AUTOSAR XML (schema 00048)
package /ComponentTypes
  swc implementation Common_Safety_Implementation: behavior=Common_Safety_InternalBehavior
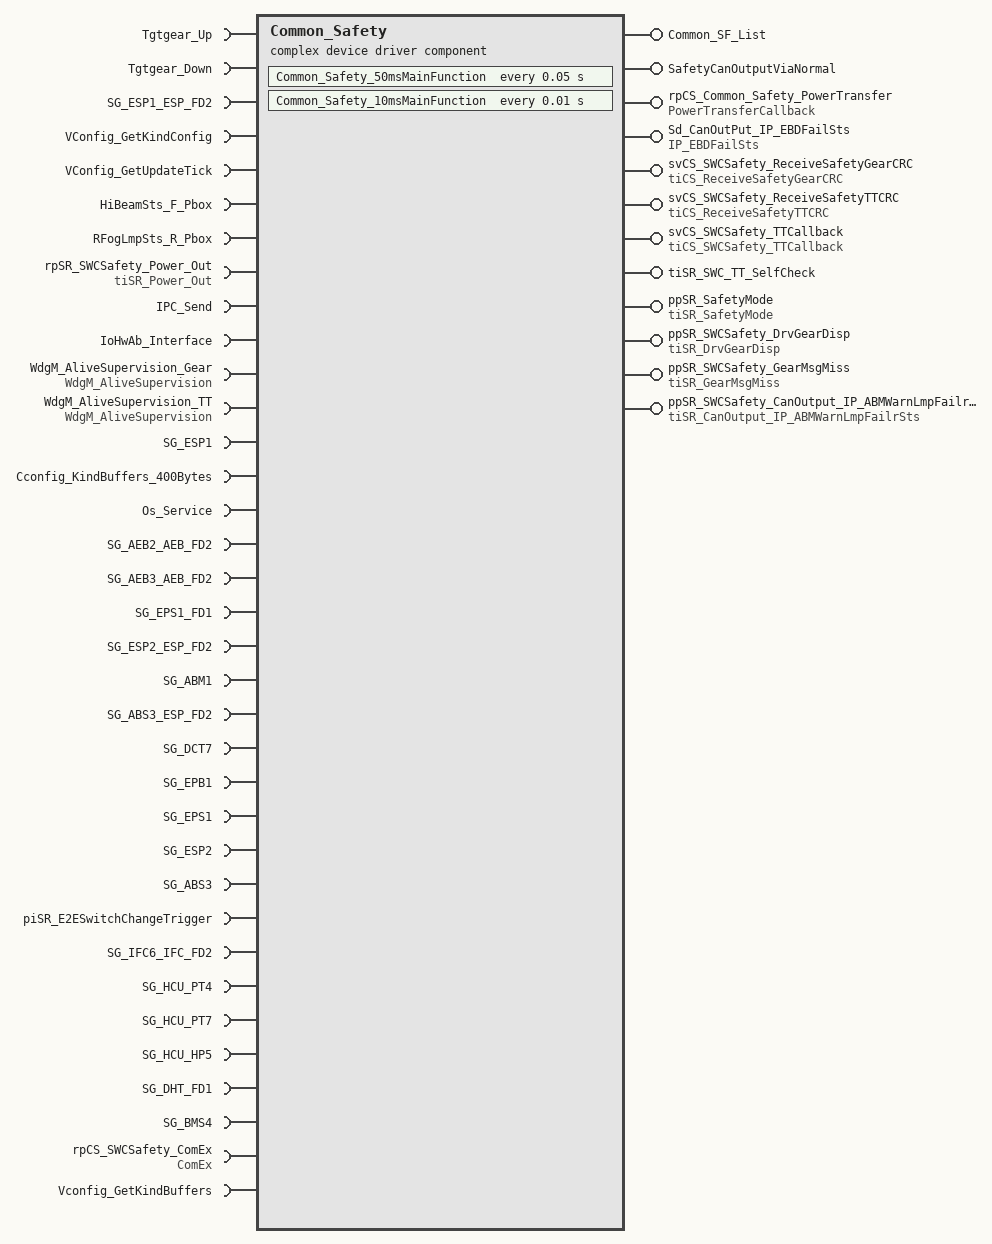
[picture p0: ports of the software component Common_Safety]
  complex device driver sw component type Common_Safety
    5 x require port:
      Tgtgear_Up: nonqueued-receiver-com-spec{data-element=Tgtgear_Up, alive-timeout=0.2, enable-update=true, filter=data-filter-type=ALWAYS, handle-never-received=true, init-value=0}, required-interface=Tgtgear_Up
      Tgtgear_Down: nonqueued-receiver-com-spec{data-element=Tgtgear_Down, alive-timeout=0.2, enable-update=true, filter=data-filter-type=ALWAYS, handle-never-received=true, init-value=0}, required-interface=Tgtgear_Down
      SG_ESP1_ESP_FD2: nonqueued-receiver-com-spec{data-element=SG_ESP1_ESP_FD2, uses-end-to-end-protection=true, alive-timeout=0.2, enable-update=true, handle-never-received=true, init-value=fields=[BTCActv_0x137:0, CheckSum_ESP1_0x137:0, dummy_ESP_FD2_16:0, dummy_ESP_FD2_17:0, dummy_ESP_FD2_18:0, dummy_ESP_FD2_19:0, dummy_ESP_FD2_20:0, ESP_MasterCylBrkPress_0x137:0, ESP_MasterCylBrkPressVld_0x137:0, ESPActvInfoLmp_0x137:0, ESPBrkLmpCtrl_0x137:0, ESPFailSts_0x137:0, ESPFuncOffSts_0x137:0, MSRActv_0x137:0, PTCActv_0x137:0, RollingCounter_ESP1_0x137:0, VDCActv_0x137:0]}, required-interface=SG_ESP1_ESP_FD2
      VConfig_GetKindConfig: client-com-spec=Operation_VConfig_GetKindConfig, required-interface=VConfig_GetKindConfig
      VConfig_GetUpdateTick: client-com-spec=OperationVConfig_GetUpdateTick, required-interface=VConfig_GetUpdateTick
    provide port Common_SF_List: provided-com-specs=[{operation=Deinit, queue-length=1}, {operation=Int, queue-length=1}], provided-interface=Common_SF_List
    5 x require port:
      HiBeamSts_F_Pbox: nonqueued-receiver-com-spec{data-element=HiBeamSts_F_Pbox, alive-timeout=0.5, filter=data-filter-type=ALWAYS, handle-never-received=true, init-value=0}, required-interface=HiBeamSts_F_Pbox
      RFogLmpSts_R_Pbox: nonqueued-receiver-com-spec{data-element=RFogLmpSts_R_Pbox, alive-timeout=0.5, filter=data-filter-type=ALWAYS, handle-never-received=true, init-value=0}, required-interface=RFogLmpSts_R_Pbox
      rpSR_SWCSafety_Power_Out: nonqueued-receiver-com-spec{data-element=SystemStateOut, filter=data-filter-type=ALWAYS}, required-interface=tiSR_Power_Out
      IPC_Send: client-com-spec=IPC_Send, required-interface=IPC_Send
      IoHwAb_Interface: required-com-specs=[SetHsLsOutput, SetPeriodAndDuty, SetDuty, SetPin, GetPin, GetVoltage], required-interface=IoHwAb_Interface
    provide port SafetyCanOutputViaNormal: provided-interface=SafetyCanOutputViaNormal
      provided-com-specs:
        data-element=CheckSum_IP2, init-value=0
        data-element=RollingCounter_IP2, init-value=0
        data-element=IP_VINcompr, init-value=0
        data-element=IP_VehTotDistanceValid, init-value=0
        data-element=IP_VehTotDistance, init-value=0
        data-element=IP_PassSeatBeltWarnLmpFailSts, init-value=0
        data-element=IP_VehSpdUnit, init-value=0
        data-element=IP_FuelLvlInfo, init-value=0
        data-element=IP_FuelLvlLowLmpSts, init-value=0
        data-element=IP_Err, init-value=0
        data-element=IP_EngOilPressLowLmpSts, init-value=0
        data-element=IP_DrvSeatBeltWarnLmpFailSts, init-value=0
        data-element=IP_BattChrgLmpSts, init-value=0
        data-element=IP_ACCErr, init-value=0
        data-element=IP_ABMWarnLmpFailrSts, init-value=0
        data-element=dummy_HUT_IP2_0, init-value=0
        data-element=IP_RemainDistance, init-value=0
        data-element=IP_InstFuelConsUnit, init-value=0
        data-element=IP_AvgFuelCons, init-value=0
        data-element=IP_InstFuelCons, init-value=0
        data-element=IP_CurrTheme, init-value=0
        data-element=IP_VehSpdDisp, init-value=0
        data-element=IP_FuelMainTankR, init-value=0
        data-element=IP_FuelAuxTankR, init-value=0
        data-element=IP_VelSpdDisp_Mile, init-value=0
        data-element=IP_LagueSet, init-value=0
        data-element=IP_EBDFailSts, init-value=0
    require port WdgM_AliveSupervision_Gear: client-com-spec=CheckpointReached, required-interface=WdgM_AliveSupervision
    require port WdgM_AliveSupervision_TT: client-com-spec=CheckpointReached, required-interface=WdgM_AliveSupervision
    provide port rpCS_Common_Safety_PowerTransfer: provided-com-specs=[{operation=Nomal2StandbyCallback, queue-length=1}, {operation=Standby2NomalCallback, queue-length=1}], provided-interface=PowerTransferCallback
    require port SG_ESP1: nonqueued-receiver-com-spec{data-element=SG_ESP1, uses-end-to-end-protection=true, alive-timeout=0.2, enable-update=true, handle-never-received=true, init-value=fields=[BTCActv_0x149:0, CheckSum_ESP1_0x149:0, dummy_ESP1_0:0, dummy_ESP1_1:0, dummy_ESP1_2:0, dummy_ESP1_3:0, dummy_ESP1_4:0, ESP_MasterCylBrkPress_0x149:0, ESP_MasterCylBrkPressVld_0x149:1, ESPActvInfoLmp_0x149:0, ESPBrkLmpCtrl_0x149:0, ESPFailSts_0x149:0, ESPFuncOffSts_0x149:0, MSRActv_0x149:0, PTCActv_0x149:0, RollingCounter_ESP1_0x149:0, VDCActv_0x149:0]}, required-interface=SG_ESP1
    provide port Sd_CanOutPut_IP_EBDFailSts: nonqueued-sender-com-spec{data-element=IP_EBDFailSts, init-value=0}, provided-interface=IP_EBDFailSts
    require port Cconfig_KindBuffers_400Bytes: nonqueued-receiver-com-spec{data-element=CconfigKind_400Bytes, filter=data-filter-type=ALWAYS, init-value=400 x 0}, required-interface=Cconfig_KindBuffers_400Bytes
    require port Os_Service: required-com-specs=[GetElapsedValue, GetCounterValue], required-interface=Os_Service
    provide port svCS_SWCSafety_ReceiveSafetyGearCRC: server-com-spec{operation=Callback, queue-length=1}, provided-interface=tiCS_ReceiveSafetyGearCRC
    provide port svCS_SWCSafety_ReceiveSafetyTTCRC: server-com-spec{operation=Callback, queue-length=1}, provided-interface=tiCS_ReceiveSafetyTTCRC
    12 x require port:
      SG_AEB2_AEB_FD2: nonqueued-receiver-com-spec{data-element=SG_AEB2_AEB_FD2, uses-end-to-end-protection=true, alive-timeout=0.5, enable-update=true, handle-never-received=true, init-value=fields=[AEB_JA_Resp:1, AEB_PedResp:1, AEB_VehResp:1, Checksum_AEB2:0, FCW_Snvty:0, RollingCounter_AEB2:0, dummy_AEB_FD2_8:0, dummy_AEB_FD2_9:0, dummy_AEB_FD2_10:0, dummy_AEB_FD2_11:0, dummy_AEB_FD2_12:0, dummy_AEB_FD2_13:0, dummy_AEB_FD2_14:0]}, required-interface=SG_AEB2_AEB_FD2
      SG_AEB3_AEB_FD2: nonqueued-receiver-com-spec{data-element=SG_AEB3_AEB_FD2, uses-end-to-end-protection=true, alive-timeout=0.5, enable-update=true, handle-never-received=true, init-value=fields=[AEB_JA_Warn:0, AEB_JABrkTrig:0, AEB_JAFuncSts:0, AEB_PedTrig:0, AEB_VehTrig:0, Checksum_AEB3:0, FCW_AEB_PedFctSts:0, FCW_AEB_VehFctSts:0, FCW_Warn:0, RollingCounter_AEB3:0, dummy_AEB_FD2_15:0, dummy_AEB_FD2_16:0, dummy_AEB_FD2_17:0, dummy_AEB_FD2_18:0, dummy_AEB_FD2_19:0, dummy_AEB_FD2_20:0, dummy_AEB_FD2_21:0]}, required-interface=SG_AEB3_AEB_FD2
      SG_EPS1_FD1: nonqueued-receiver-com-spec{data-element=SG_EPS1_FD1, uses-end-to-end-protection=true, alive-timeout=0.2, enable-update=true, handle-never-received=true, init-value=fields=[CheckSum_EPS1_0x147:0, dummy_EPS_FD1_0:0, dummy_EPS_FD1_1:0, dummy_EPS_FD1_2:0, dummy_EPS_FD1_3:0, dummy_EPS_FD1_4:0, dummy_EPS_FD1_5:0, dummy_EPS_FD1_6:0, dummy_EPS_FD1_7:0, EPS_FailSts_0x147:0, EPS_SteerMod_0x147:0, EPS_TrqSnsrSts_0x147:0, RollingCounter_EPS1_0x147:0]}, required-interface=SG_EPS1_FD1
      SG_ESP2_ESP_FD2: nonqueued-receiver-com-spec{data-element=SG_ESP2_ESP_FD2, uses-end-to-end-protection=true, alive-timeout=0.2, enable-update=true, handle-never-received=true, init-value=fields=[ABAActv_0x137:0, ABAavailable_0x137:0, ABPActv_0x137:0, ABPAvailable_0x137:0, AEBAvailable_0x137:0, AEBBAActv_0x137:0, AEBIBActv_0x137:0, AVHErrSts_0x137:0, AVHSts_0x137:0, AWBActv_0x137:0, AWBAvailable_0x137:0, BrkDskOvrheatd_0x137:0, CDDActv_0x137:0, CDDAvailable_0x137:0, CDPActv_0x137:0, CheckSum_ESP2_0x137:0, dummy_ESP_FD2_8:0, dummy_ESP_FD2_9:0, dummy_ESP_FD2_10:0, dummy_ESP_FD2_11:0, dummy_ESP_FD2_12:0, dummy_ESP_FD2_13:0, dummy_ESP_FD2_14:0, dummy_ESP_FD2_15:0, HDCCtrl_0x137:0, HDCFault_0x137:0, NoBrkForce_0x137:0, RollingCounter_ESP2_0x137:0, VehStandstill_0x137:0]}, required-interface=SG_ESP2_ESP_FD2
      SG_ABM1: nonqueued-receiver-com-spec{data-element=SG_ABM1, uses-end-to-end-protection=true, alive-timeout=5, enable-update=true, handle-never-received=true, init-value=fields=[AirbFailLmpCmd:0, CheckSum_ABM1:0, DrvSBR:0, DrvSBR_Visual:0, PassSBR:0, PassSBR_Visual:0, RollingCounter_ABM1:0, SecRowLSBR:0, SecRowLSBR_Visual:0, SecRowMidSBR:0, SecRowMidSBR_Visual:0, SecRowRSBR:0, SecRowRSBR_Visual:0, CrashOutputSts:0, dummy_ABM1_0:0, dummy_ABM1_1:0, dummy_ABM1_2:0, dummy_ABM1_3:0, dummy_ABM1_4:0, dummy_ABM1_5:0]}, required-interface=SG_ABM1
      SG_ABS3_ESP_FD2: nonqueued-receiver-com-spec{data-element=SG_ABS3_ESP_FD2, uses-end-to-end-protection=true, alive-timeout=0.2, enable-update=true, handle-never-received=true, init-value=fields=[ABSActv_0x137:0, ABSFailSts_0x137:1, CheckSum_ABS3_0x137:0, dummy_ESP_FD2_37:0, dummy_ESP_FD2_38:0, dummy_ESP_FD2_39:0, dummy_ESP_FD2_40:0, EBDActv_0x137:0, EBDFailSts_0x137:0, RollingCounter_ABS3_0x137:0, VehOdoInfo_0x137:0, VehOdoInfoSts_0x137:1, VehSpd_0x137:0, VehSpdVld_0x137:0]}, required-interface=SG_ABS3_ESP_FD2
      SG_DCT7: nonqueued-receiver-com-spec{data-element=SG_DCT7, uses-end-to-end-protection=true, alive-timeout=0.5, enable-update=true, handle-never-received=true, init-value=fields=[CheckSum_DCT7:0, DCT_PrsBrk_Warn:0, DCT_RaceModeSts:0, DCT_ShftNotAlwd_Warn:0, DCT_ShftRecom_M:0, DrvAutoGearDisp:0, DrvWarnMsg:0, RollingCounter_DCT7:0, DrvFaiMsg_0x235:0, DrvGearDispSts_0x235:0, DrvModDisp_0x235:0, DrvModDispSts_0x235:0, dummy_DCT7_0:0, dummy_DCT7_1:0, dummy_DCT7_2:0, dummy_DCT7_3:0, dummy_DCT7_4:0, dummy_DCT7_5:0]}, required-interface=SG_DCT7
      SG_EPB1: nonqueued-receiver-com-spec{data-element=SG_EPB1, uses-end-to-end-protection=true, alive-timeout=0.2, enable-update=true, handle-never-received=true, init-value=fields=[CheckSum_EPB1:0, EPBErrSts:0, EPBRedLmpSts:0, EPBSts:0, EPBTextDisp:0, PressBrakePedalPointOut:0, RollingCounter_EPB1:0, dummy_EPB1_0:0, dummy_EPB1_1:0, dummy_EPB1_2:0, dummy_EPB1_3:0, dummy_EPB1_4:0, dummy_EPB1_5:0, dummy_EPB1_6:0, dummy_EPB1_7:0]}, required-interface=SG_EPB1
      SG_EPS1: nonqueued-receiver-com-spec{data-element=SG_EPS1, uses-end-to-end-protection=true, alive-timeout=0.2, enable-update=true, handle-never-received=true, init-value=fields=[CheckSum_EPS1_0x168:0, dummy_EPS1_0:0, dummy_EPS1_1:0, dummy_EPS1_2:0, dummy_EPS1_3:0, dummy_EPS1_4:0, dummy_EPS1_5:0, dummy_EPS1_6:0, dummy_EPS1_7:0, EPS_FailSts_0x168:0, EPS_SteerMod_0x168:0, EPS_TrqSnsrSts_0x168:1, RollingCounter_EPS1_0x168:0]}, required-interface=SG_EPS1
      SG_ESP2: nonqueued-receiver-com-spec{data-element=SG_ESP2, uses-end-to-end-protection=true, alive-timeout=0.2, enable-update=true, handle-never-received=true, init-value=fields=[DrivingModDis:0, DrivingModReq_ESP:0, TAB_Available:0, TAB_Sts:0, ABAActv_0x145:0, ABAavailable_0x145:0, ABPActv_0x145:0, ABPAvailable_0x145:0, AEBAvailable_0x145:0, AEBBAActv_0x145:0, AEBIBActv_0x145:0, AVHErrSts_0x145:0, AVHSts_0x145:0, AWBActv_0x145:0, AWBAvailable_0x145:0, BrkDskOvrheatd_0x145:0, CDDActv_0x145:0, CDDAvailable_0x145:0, CDPActv_0x145:0, CheckSum_ESP2_0x145:0, dummy_ESP2_0:0, dummy_ESP2_1:0, dummy_ESP2_2:0, dummy_ESP2_3:0, dummy_ESP2_4:0, dummy_ESP2_5:0, dummy_ESP2_6:0, dummy_ESP2_7:0, HDCCtrl_0x145:0, HDCFault_0x145:0, NoBrkForce_0x145:0, RollingCounter_ESP2_0x145:0, VehStandstill_0x145:0]}, required-interface=SG_ESP2
      SG_ABS3: nonqueued-receiver-com-spec{data-element=SG_ABS3, uses-end-to-end-protection=true, alive-timeout=0.2, enable-update=true, handle-never-received=true, init-value=fields=[ABSActv_0x265:0, ABSFailSts_0x265:1, CheckSum_ABS3_0x265:0, dummy_ABS3_0:0, dummy_ABS3_1:0, dummy_ABS3_2:0, dummy_ABS3_3:0, EBDActv_0x265:0, EBDFailSts_0x265:0, RollingCounter_ABS3_0x265:0, VehOdoInfo_0x265:0, VehOdoInfoSts_0x265:1, VehSpd_0x265:0, VehSpdVld_0x265:0]}, required-interface=SG_ABS3
      piSR_E2ESwitchChangeTrigger: nonqueued-receiver-com-spec{data-element=Element, filter=data-filter-type=ALWAYS, init-value=0}, required-interface=piSR_E2ESwitchChangeTrigger
    provide port svCS_SWCSafety_TTCallback: server-com-spec{operation=Operation, queue-length=1}, provided-interface=tiCS_SWCSafety_TTCallback
    provide port tiSR_SWC_TT_SelfCheck: nonqueued-sender-com-spec{data-element=Element, init-value=0}, provided-interface=tiSR_SWC_TT_SelfCheck
    provide port ppSR_SafetyMode: server-com-spec{operation=Operation, queue-length=1}, provided-interface=tiSR_SafetyMode
    7 x require port:
      SG_IFC6_IFC_FD2: nonqueued-receiver-com-spec{data-element=SG_IFC6_IFC_FD2, uses-end-to-end-protection=true, alive-timeout=0.5, enable-update=true, filter=data-filter-type=ALWAYS, handle-never-received=true, init-value=fields=[Checksum_IFC6:0, dummy_IFC_FD2_17:0, dummy_IFC_FD2_18:0, dummy_IFC_FD2_19:0, dummy_IFC_FD2_20:0, IFC_NextLeLane_dy:2496, IFC_NextRiLane_dy:2496, RollingCounter_IFC6:0]}, required-interface=SG_IFC6_IFC_FD2
      SG_HCU_PT4: nonqueued-receiver-com-spec{data-element=SG_HCU_PT4, uses-end-to-end-protection=true, alive-timeout=1, enable-update=true, filter=data-filter-type=ALWAYS, handle-never-received=true, init-value=fields=[CarWashMode_Sts:0, CarWashMode_StsDisp:0, Checksum_HCU_PT4:0, dummy_HCU_PT4_0:0, dummy_HCU_PT4_1:0, dummy_HCU_PT4_2:0, dummy_HCU_PT4_3:0, dummy_HCU_PT4_4:0, dummy_HCU_PT4_5:0, dummy_HCU_PT4_6:0, dummy_HCU_PT4_7:0, HCU_ACStsReq:2, HCU_BattPowerRedWarn:0, HCU_ConnectChrgLine_Indcn:0, HCU_EgyRecFB:0, HCU_EnerSavePowerMod:0, HCU_InhbChrgInfo:0, HCU_OilTankCoverSts:0, HCU_OPDFail:0, HCU_RefuReq:0, HCU_RemoveChrgLine_Indcn:0, HCU_Shift_P_Indcn:0, HCU_SOCLow_Indcn:0, HCU_WadeModeSetSts:0, OPDParkWarnReq:0, RollingCounter_HCU_PT4:0]}, required-interface=SG_HCU_PT4
      SG_HCU_PT7: nonqueued-receiver-com-spec{data-element=SG_HCU_PT7, uses-end-to-end-protection=true, alive-timeout=0.5, enable-update=true, filter=data-filter-type=ALWAYS, handle-never-received=true, init-value=fields=[CheckSum_HCU_PT7:0, dummy_HCU_PT7_0:0, dummy_HCU_PT7_1:0, dummy_HCU_PT7_2:0, dummy_HCU_PT7_3:0, dummy_HCU_PT7_4:0, dummy_HCU_PT7_5:0, dummy_HCU_PT7_6:0, HCU_12VSysErr_1:0, HCU_12VSysErr_2:0, HCU_12VSysErrLmpSts:0, HCU_EnrgFlowInd:0, HCU_HybSysErr_1:0, HCU_HybSysErr_2:0, HCU_HybSysErr_3:0, HCU_HybSysErr_4:0, HCU_HybSysErr_5:0, HCU_HybSysErr_6:0, HCU_HybSysErr_7:0, HCU_HybSysErrLmpSts:0, HCU_ModSwtFail:0, HCU_OPDLmpSts:0, HCU_OPDSts:0, HCU_PowerRedWarnLmpCmd:0, HCU_RdyLmpSts:0, RollingCounter_HCU_PT7:0]}, required-interface=SG_HCU_PT7
      SG_HCU_HP5: nonqueued-receiver-com-spec{data-element=SG_HCU_HP5, uses-end-to-end-protection=true, alive-timeout=0.5, enable-update=true, filter=data-filter-type=ALWAYS, handle-never-received=true, init-value=fields=[Checksum_HCU_HP5:0, DrvFaiMsg_0x201:0, DrvGearDisp:0, DrvGearDispSts_0x201:0, DrvModDisp_0x201:0, DrvModDispSts_0x201:0, dummy_HCU_HP5_0:0, dummy_HCU_HP5_1:0, dummy_HCU_HP5_2:0, dummy_HCU_HP5_3:0, dummy_HCU_HP5_4:0, HCU_EnrgFlowInd_DHT:0, HCU_PrsBrkWarn:0, HCU_ShftNotAlwd_Warn:0, RollingCounter_HCU_HP5:0]}, required-interface=SG_HCU_HP5
      SG_DHT_FD1: nonqueued-receiver-com-spec{data-element=SG_DHT_FD1, uses-end-to-end-protection=true, alive-timeout=0.1, enable-update=true, filter=data-filter-type=ALWAYS, handle-never-received=true, init-value=fields=[CheckSum_DHT1:0, dummy_DHT_FD1_8:0, dummy_DHT_FD1_9:0, dummy_DHT_FD1_10:0, dummy_DHT_FD1_11:0, dummy_DHT_FD1_12:0, dummy_DHT_FD1_13:0, RollingCounter_DHT1:0, TCU_ClutchHotWarning:0, TCU_ErrCategory:0]}, required-interface=SG_DHT_FD1
      SG_BMS4: nonqueued-receiver-com-spec{data-element=SG_BMS4, uses-end-to-end-protection=true, alive-timeout=0.1, enable-update=true, filter=data-filter-type=ALWAYS, handle-never-received=true, init-value=fields=[BMS_BattPoweErr:0, BMS_ErrCategory:0, BMS_PackCurr:0, BMS_PackVolt:178, BMS_PowerDownCmplt:0, CheckSum_BMS4:0, dummy_BMS4_0:0, dummy_BMS4_1:0, dummy_BMS4_2:0, dummy_BMS4_3:0, dummy_BMS4_4:0, RollingCounter_BMS4:0]}, required-interface=SG_BMS4
      rpCS_SWCSafety_ComEx: required-com-specs=[SendSignal, ReceiveSignal, GetRxE2EStatus], required-interface=ComEx
    provide port ppSR_SWCSafety_DrvGearDisp: nonqueued-sender-com-spec{data-element=Element, init-value=0}, provided-interface=tiSR_DrvGearDisp
    provide port ppSR_SWCSafety_GearMsgMiss: nonqueued-sender-com-spec{data-element=Element, init-value=0}, provided-interface=tiSR_GearMsgMiss
    require port Vconfig_GetKindBuffers: nonqueued-receiver-com-spec{data-element=AllKinds, filter=data-filter-type=ALWAYS, init-value=600 x 0}, required-interface=Vconfig_GetKindBuffers
    provide port ppSR_SWCSafety_CanOutput_IP_ABMWarnLmpFailrSts: nonqueued-sender-com-spec{data-element=Element, init-value=0}, provided-interface=tiSR_CanOutput_IP_ABMWarnLmpFailrSts
    behavior Common_Safety_InternalBehavior: data-type-mapping=[DataTypeMappings_DEV, DataTypeMappings_DEV], port-api-option{enable-take-address=true, error-handling=NO-TRANSFORMER-ERROR-HANDLING, indirect-api=false, port=Common_SF_List}
      exclusive area ExclusiveArea_Safety
      init event Gear_InitEvent: start-on-event=Common_Safety_Init
      timing event TMT_Gear_MainFunction: start-on-event=Common_Safety_50msMainFunction, period=0.05
      timing event TMT_TT_MainFunction: start-on-event=Common_Safety_10msMainFunction, period=0.01
      8 x operation invoked event:
        OIT_Common_SF_List_Deinit_Common_SF_List_Deinit: start-on-event=Common_SF_List_Deinit, operation=Common_SF_List.Deinit
        OIT_Common_SF_List_Int_Common_SF_List_Int: start-on-event=Common_SF_List_Int, operation=Common_SF_List.Int
        OIT_Common_Safety_Nomal2Standby_Callbcak_rpCS_Common_Safety_PowerTransfer_Nomal2StandbyCallback: start-on-event=Common_Safety_Nomal2Standby_Callbcak, operation=rpCS_Common_Safety_PowerTransfer.Nomal2StandbyCallback
        OIT_Common_GateWay_Standby2Nomal_Callbcak_rpCS_Common_Safety_PowerTransfer_Standby2NomalCallback: start-on-event=Common_Safety_Standby2Nomal_Callbcak, operation=rpCS_Common_Safety_PowerTransfer.Standby2NomalCallback
        OIT_Runnable_svCS_SWCSafety_ReceiveSafetyGearCRC_Callback: start-on-event=svCS_SWCSafety_ReceiveSafetyGearCRC_Callback, operation=svCS_SWCSafety_ReceiveSafetyGearCRC.Callback
        OIT_Runnable_svCS_SWCSafety_ReceiveSafetyTTCRC_Callback: start-on-event=svCS_SWCSafety_ReceiveSafetyTTCRC_Callback, operation=svCS_SWCSafety_ReceiveSafetyTTCRC.Callback
        OIT_svCS_SWCSafety_TTCallback_Operation_svCS_SWCSafety_TTCallback_Operation: start-on-event=svCS_SWCSafety_TTCallback_Operation, operation=svCS_SWCSafety_TTCallback.Operation
        OIT_ppSR_SafetyMode_Operation_ppSR_SafetyMode_Operation: start-on-event=SafetyMode_Operation, operation=ppSR_SafetyMode.Operation
      11 x runnable:
        Common_Safety_Init
        Common_Safety_50msMainFunction: can-enter-exclusive-area=ExclusiveArea_Safety
          data-read-access:
            access REC_rpSR_SWCSafety_Power_Out_SystemStateOut: accessed-variable=rpSR_SWCSafety_Power_Out.SystemStateOut
          data-receive-point-by-arguments:
            5 x access:
              REC_Tgtgear_Down_Tgtgear_Down: accessed-variable=Tgtgear_Down.Tgtgear_Down
              REC_Tgtgear_Up_Tgtgear_Up: accessed-variable=Tgtgear_Up.Tgtgear_Up
              REC_SG_ESP1_ESP_FD2_SG_ESP1_ESP_FD2: accessed-variable=SG_ESP1_ESP_FD2.SG_ESP1_ESP_FD2
              REC_HiBeamSts_F_Pbox_HiBeamSts_F_Pbox: accessed-variable=HiBeamSts_F_Pbox.HiBeamSts_F_Pbox
              REC_RFogLmpSts_R_Pbox_RFogLmpSts_R_Pbox: accessed-variable=RFogLmpSts_R_Pbox.RFogLmpSts_R_Pbox
          data-send-points:
            access SEND_ppSR_SWCSafety_DrvGearDisp_Element: accessed-variable=ppSR_SWCSafety_DrvGearDisp.Element
            access SEND_ppSR_SWCSafety_GearMsgMiss_Element: accessed-variable=ppSR_SWCSafety_GearMsgMiss.Element
          sync call SC_IPC_Send_IPC_Send: operation=IPC_Send.IPC_Send
          sync call SC_WdgM_AliveSupervision_Gear_CheckpointReached: operation=WdgM_AliveSupervision_Gear.CheckpointReached
        Common_Safety_10msMainFunction: can-enter-exclusive-area=ExclusiveArea_Safety
          data-read-access:
            access REC_rpSR_SWCSafety_Power_Out_SystemStateOut: accessed-variable=rpSR_SWCSafety_Power_Out.SystemStateOut
          data-receive-point-by-arguments:
            26 x access:
              REC_HiBeamSts_F_Pbox_HiBeamSts_F_Pbox: accessed-variable=HiBeamSts_F_Pbox.HiBeamSts_F_Pbox
              REC_RFogLmpSts_R_Pbox_RFogLmpSts_R_Pbox: accessed-variable=RFogLmpSts_R_Pbox.RFogLmpSts_R_Pbox
              REC_SG_ESP1_ESP_FD2_SG_ESP1_ESP_FD2: accessed-variable=SG_ESP1_ESP_FD2.SG_ESP1_ESP_FD2
              REC_Tgtgear_Down_Tgtgear_Down: accessed-variable=Tgtgear_Down.Tgtgear_Down
              REC_Tgtgear_Up_Tgtgear_Up: accessed-variable=Tgtgear_Up.Tgtgear_Up
              REC_SG_ESP1_SG_ESP1: accessed-variable=SG_ESP1.SG_ESP1
              REC_Cconfig_KindBuffers_400Bytes_CconfigKind_400Bytes: accessed-variable=Cconfig_KindBuffers_400Bytes.CconfigKind_400Bytes
              REC_SG_AEB2_AEB_FD2_SG_AEB2_AEB_FD2: accessed-variable=SG_AEB2_AEB_FD2.SG_AEB2_AEB_FD2
              REC_SG_AEB3_AEB_FD2_SG_AEB3_AEB_FD2: accessed-variable=SG_AEB3_AEB_FD2.SG_AEB3_AEB_FD2
              REC_SG_EPS1_FD1_SG_EPS1_FD1: accessed-variable=SG_EPS1_FD1.SG_EPS1_FD1
              REC_SG_ESP2_ESP_FD2_SG_ESP2_ESP_FD2: accessed-variable=SG_ESP2_ESP_FD2.SG_ESP2_ESP_FD2
              REC_SG_ABM1_SG_ABM1: accessed-variable=SG_ABM1.SG_ABM1
              REC_SG_ABS3_ESP_FD2_SG_ABS3_ESP_FD2: accessed-variable=SG_ABS3_ESP_FD2.SG_ABS3_ESP_FD2
              REC_SG_DCT7_SG_DCT7: accessed-variable=SG_DCT7.SG_DCT7
              REC_SG_EPB1_SG_EPB1: accessed-variable=SG_EPB1.SG_EPB1
              REC_SG_EPS1_SG_EPS1: accessed-variable=SG_EPS1.SG_EPS1
              REC_SG_ESP2_SG_ESP2: accessed-variable=SG_ESP2.SG_ESP2
              REC_SG_ABS3_SG_ABS3: accessed-variable=SG_ABS3.SG_ABS3
              REC_piSR_E2ESwitchChangeTrigger_Element: accessed-variable=piSR_E2ESwitchChangeTrigger.Element
              REC_SG_IFC6_IFC_FD2_SG_IFC6_IFC_FD2: accessed-variable=SG_IFC6_IFC_FD2.SG_IFC6_IFC_FD2
              REC_SG_HCU_PT4_SG_HCU_PT4: accessed-variable=SG_HCU_PT4.SG_HCU_PT4
              REC_SG_HCU_PT7_SG_HCU_PT7: accessed-variable=SG_HCU_PT7.SG_HCU_PT7
              REC_SG_BMS4_SG_BMS4: accessed-variable=SG_BMS4.SG_BMS4
              REC_SG_DHT_FD1_SG_DHT_FD1: accessed-variable=SG_DHT_FD1.SG_DHT_FD1
              REC_SG_HCU_HP5_SG_HCU_HP5: accessed-variable=SG_HCU_HP5.SG_HCU_HP5
              REC_Vconfig_GetKindBuffers_Kind600Bytes: accessed-variable=Vconfig_GetKindBuffers.AllKinds
          data-send-points:
            19 x access:
              SEND_SafetyCanOutputViaNormal_Element: accessed-variable=SafetyCanOutputViaNormal.CheckSum_IP2
              SEND_SafetyCanOutputViaNormal_IP_ABMWarnLmpFailrSts: accessed-variable=SafetyCanOutputViaNormal.IP_ABMWarnLmpFailrSts
              SEND_SafetyCanOutputViaNormal_IP_ACCErr: accessed-variable=SafetyCanOutputViaNormal.IP_ACCErr
              SEND_SafetyCanOutputViaNormal_IP_BattChrgLmpSts: accessed-variable=SafetyCanOutputViaNormal.IP_BattChrgLmpSts
              SEND_SafetyCanOutputViaNormal_IP_DrvSeatBeltWarnLmpFailSts: accessed-variable=SafetyCanOutputViaNormal.IP_DrvSeatBeltWarnLmpFailSts
              SEND_SafetyCanOutputViaNormal_IP_EngOilPressLowLmpSts: accessed-variable=SafetyCanOutputViaNormal.IP_EngOilPressLowLmpSts
              SEND_SafetyCanOutputViaNormal_IP_Err: accessed-variable=SafetyCanOutputViaNormal.IP_Err
              SEND_SafetyCanOutputViaNormal_IP_FuelLvlInfo: accessed-variable=SafetyCanOutputViaNormal.IP_FuelLvlInfo
              SEND_SafetyCanOutputViaNormal_IP_FuelLvlLowLmpSts: accessed-variable=SafetyCanOutputViaNormal.IP_FuelLvlLowLmpSts
              SEND_SafetyCanOutputViaNormal_IP_PassSeatBeltWarnLmpFailSts: accessed-variable=SafetyCanOutputViaNormal.IP_PassSeatBeltWarnLmpFailSts
              SEND_SafetyCanOutputViaNormal_IP_VINcompr: accessed-variable=SafetyCanOutputViaNormal.IP_VINcompr
              SEND_SafetyCanOutputViaNormal_IP_VehSpdUnit: accessed-variable=SafetyCanOutputViaNormal.IP_VehSpdUnit
              SEND_SafetyCanOutputViaNormal_IP_VehTotDistance: accessed-variable=SafetyCanOutputViaNormal.IP_VehTotDistance
              SEND_SafetyCanOutputViaNormal_IP_VehTotDistanceValid: accessed-variable=SafetyCanOutputViaNormal.IP_VehTotDistanceValid
              SEND_SafetyCanOutputViaNormal_RollingCounter_IP2: accessed-variable=SafetyCanOutputViaNormal.RollingCounter_IP2
              SEND_SafetyCanOutputViaNormal_dummy_HUT_IP2_0: accessed-variable=SafetyCanOutputViaNormal.dummy_HUT_IP2_0
              SEND_IP_EBDFailSts_IP_EBDFailSts: accessed-variable=Sd_CanOutPut_IP_EBDFailSts.IP_EBDFailSts
              SEND_tiSR_SWC_TT_SelfCheck_Element: accessed-variable=tiSR_SWC_TT_SelfCheck.Element
              SEND_ppSR_SWCSafety_CanOutput_IP_ABMWarnLmpFailrSts_Element: accessed-variable=ppSR_SWCSafety_CanOutput_IP_ABMWarnLmpFailrSts.Element
          11 x sync call:
            SC_IPC_Send_IPC_Send: operation=IPC_Send.IPC_Send
            SC_VConfig_GetUpdateTick_OperationVConfig_GetUpdateTick: operation=VConfig_GetUpdateTick.OperationVConfig_GetUpdateTick
            SC_VConfig_GetKindConfig_Operation_VConfig_GetKindConfig: operation=VConfig_GetKindConfig.Operation_VConfig_GetKindConfig
            SC_WdgM_AliveSupervision_TT_CheckpointReached: operation=WdgM_AliveSupervision_TT.CheckpointReached
            SC_Os_Service_GetCounterValue: operation=Os_Service.GetCounterValue
            SC_Os_Service_GetElapsedValue: operation=Os_Service.GetElapsedValue
            AC_IoHwAb_Interface_GetPin: operation=IoHwAb_Interface.GetPin
            AC_IoHwAb_Interface_GetVoltage: operation=IoHwAb_Interface.GetVoltage
            SC_rpCS_SWCSafety_ComEx_GetRxE2EStatus: operation=rpCS_SWCSafety_ComEx.GetRxE2EStatus
            SC_rpCS_SWCSafety_ComEx_ReceiveSignal: operation=rpCS_SWCSafety_ComEx.ReceiveSignal
            SC_rpCS_SWCSafety_ComEx_SendSignal: operation=rpCS_SWCSafety_ComEx.SendSignal
        Common_SF_List_Deinit
        Common_SF_List_Int
        Common_Safety_Nomal2Standby_Callbcak: can-be-invoked-concurrently=true
        Common_Safety_Standby2Nomal_Callbcak: can-be-invoked-concurrently=true
        svCS_SWCSafety_ReceiveSafetyGearCRC_Callback
        svCS_SWCSafety_ReceiveSafetyTTCRC_Callback
        svCS_SWCSafety_TTCallback_Operation
        SafetyMode_Operation
